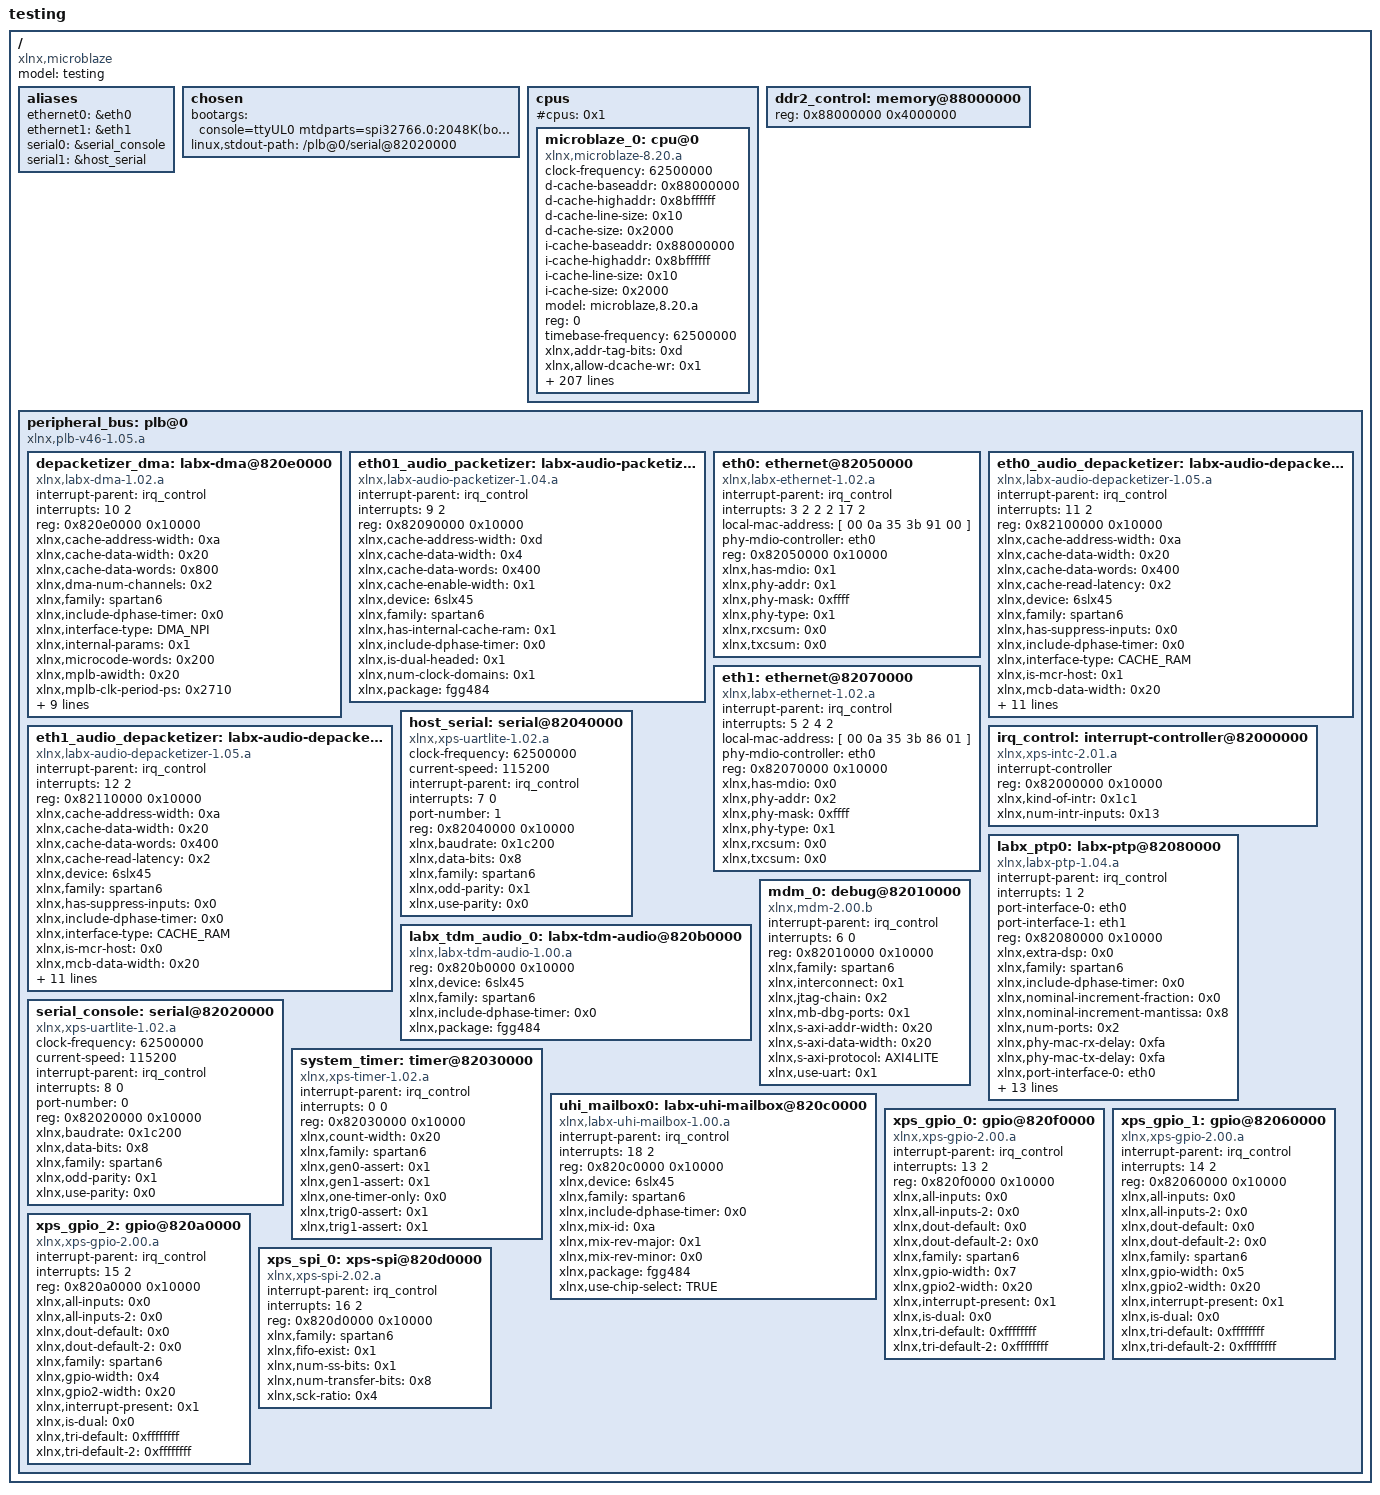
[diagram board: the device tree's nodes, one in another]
/*
 * Device Tree Generator version: 1.3
 *
 * (C) Copyright 2007-2008 Xilinx, Inc.
 * (C) Copyright 2007-2009 Michal Simek
 *
 * Michal SIMEK <monstr@monstr.eu>
 *
 * This program is free software; you can redistribute it and/or
 * modify it under the terms of the GNU General Public License as
 * published by the Free Software Foundation; either version 2 of
 * the License, or (at your option) any later version.
 *
 * This program is distributed in the hope that it will be useful,
 * but WITHOUT ANY WARRANTY; without even the implied warranty of
 * MERCHANTABILITY or FITNESS FOR A PARTICULAR PURPOSE. See the
 * GNU General Public License for more details.
 *
 * You should have received a copy of the GNU General Public License
 * along with this program; if not, write to the Free Software
 * Foundation, Inc., 59 Temple Place, Suite 330, Boston,
 * MA 02111-1307 USA
 *
 * CAUTION: This file is automatically generated by libgen.
 * Version: Xilinx EDK 13.2 EDK_O.61xd
 *
 */

/dts-v1/;
/ {
	#address-cells = <1>;
	#size-cells = <1>;
	compatible = "xlnx,microblaze";
	model = "testing";
	aliases {
		ethernet0 = &eth0;
		ethernet1 = &eth1;
		serial0 = &serial_console;
		serial1 = &host_serial;
	} ;
	chosen {
		bootargs = "console=ttyUL0 mtdparts=spi32766.0:2048K(bootfpga),256K(boot),256K(fdt),3840K(image),2048K(rootfs),2048K(romfs),2048K(fpga),2048K(settingsfs),256K(bootenv) root=mtd4 rootfstype=romfs init=/bin/init";
		linux,stdout-path = "/plb@0/serial@82020000";
	} ;
	cpus {
		#address-cells = <1>;
		#cpus = <0x1>;
		#size-cells = <0>;
		microblaze_0: cpu@0 {
			clock-frequency = <62500000>;
			compatible = "xlnx,microblaze-8.20.a";
			d-cache-baseaddr = <0x88000000>;
			d-cache-highaddr = <0x8bffffff>;
			d-cache-line-size = <0x10>;
			d-cache-size = <0x2000>;
			device_type = "cpu";
			i-cache-baseaddr = <0x88000000>;
			i-cache-highaddr = <0x8bffffff>;
			i-cache-line-size = <0x10>;
			i-cache-size = <0x2000>;
			model = "microblaze,8.20.a";
			reg = <0>;
			timebase-frequency = <62500000>;
			xlnx,addr-tag-bits = <0xd>;
			xlnx,allow-dcache-wr = <0x1>;
			xlnx,allow-icache-wr = <0x1>;
			xlnx,archiver = "0";
			xlnx,area-optimized = <0x0>;
			xlnx,avoid-primitives = <0x0>;
			xlnx,branch-target-cache-size = <0x0>;
			xlnx,cache-byte-size = <0x2000>;
			xlnx,compiler = "0";
			xlnx,compiler-flags = "0";
			xlnx,core-clock-freq-hz = <0x5f5e100>;
			xlnx,d-axi = <0x0>;
			xlnx,d-lmb = <0x1>;
			xlnx,d-plb = <0x1>;
			xlnx,data-size = <0x20>;
			xlnx,dcache-addr-tag = <0xd>;
			xlnx,dcache-always-used = <0x1>;
			xlnx,dcache-byte-size = <0x2000>;
			xlnx,dcache-data-width = <0x0>;
			xlnx,dcache-force-tag-lutram = <0x0>;
			xlnx,dcache-interface = <0x0>;
			xlnx,dcache-line-len = <0x4>;
			xlnx,dcache-use-fsl = <0x1>;
			xlnx,dcache-use-writeback = <0x0>;
			xlnx,dcache-victims = <0x0>;
			xlnx,debug-enabled = <0x1>;
			xlnx,div-zero-exception = <0x1>;
			xlnx,dynamic-bus-sizing = <0x1>;
			xlnx,ecc-use-ce-exception = <0x0>;
			xlnx,edge-is-positive = <0x1>;
			xlnx,endianness = <0x0>;
			xlnx,extra-compiler-flags = "0";
			xlnx,family = "spartan6";
			xlnx,fault-tolerant = <0x0>;
			xlnx,fpu-exception = <0x0>;
			xlnx,freq = <0x3b9aca0>;
			xlnx,fsl-data-size = <0x20>;
			xlnx,fsl-exception = <0x0>;
			xlnx,fsl-links = <0x1>;
			xlnx,i-axi = <0x0>;
			xlnx,i-lmb = <0x1>;
			xlnx,i-plb = <0x1>;
			xlnx,icache-always-used = <0x1>;
			xlnx,icache-data-width = <0x0>;
			xlnx,icache-force-tag-lutram = <0x0>;
			xlnx,icache-interface = <0x0>;
			xlnx,icache-line-len = <0x4>;
			xlnx,icache-streams = <0x0>;
			xlnx,icache-use-fsl = <0x1>;
			xlnx,icache-victims = <0x0>;
			xlnx,ill-opcode-exception = <0x1>;
			xlnx,instance = "microblaze_0";
			xlnx,interconnect = <0x1>;
			xlnx,interconnect-m-axi-dc-read-issuing = <0x2>;
			xlnx,interconnect-m-axi-dc-write-issuing = <0x20>;
			xlnx,interconnect-m-axi-dp-read-issuing = <0x1>;
			xlnx,interconnect-m-axi-dp-write-issuing = <0x1>;
			xlnx,interconnect-m-axi-ic-read-issuing = <0x2>;
			xlnx,interconnect-m-axi-ip-read-issuing = <0x1>;
			xlnx,interrupt-is-edge = <0x0>;
			xlnx,lockstep-slave = <0x0>;
			xlnx,m-axi-d-bus-exception = <0x0>;
			xlnx,m-axi-dc-addr-width = <0x20>;
			xlnx,m-axi-dc-aruser-width = <0x5>;
			xlnx,m-axi-dc-awuser-width = <0x5>;
			xlnx,m-axi-dc-buser-width = <0x1>;
			xlnx,m-axi-dc-data-width = <0x20>;
			xlnx,m-axi-dc-exclusive-access = <0x0>;
			xlnx,m-axi-dc-protocol = "AXI4";
			xlnx,m-axi-dc-ruser-width = <0x1>;
			xlnx,m-axi-dc-supports-narrow-burst = <0x0>;
			xlnx,m-axi-dc-supports-read = <0x1>;
			xlnx,m-axi-dc-supports-threads = <0x0>;
			xlnx,m-axi-dc-supports-user-signals = <0x1>;
			xlnx,m-axi-dc-supports-write = <0x1>;
			xlnx,m-axi-dc-thread-id-width = <0x1>;
			xlnx,m-axi-dc-user-value = <0x1f>;
			xlnx,m-axi-dc-wuser-width = <0x1>;
			xlnx,m-axi-dp-addr-width = <0x20>;
			xlnx,m-axi-dp-data-width = <0x20>;
			xlnx,m-axi-dp-exclusive-access = <0x0>;
			xlnx,m-axi-dp-protocol = "AXI4LITE";
			xlnx,m-axi-dp-supports-narrow-burst = <0x0>;
			xlnx,m-axi-dp-supports-read = <0x1>;
			xlnx,m-axi-dp-supports-threads = <0x0>;
			xlnx,m-axi-dp-supports-write = <0x1>;
			xlnx,m-axi-dp-thread-id-width = <0x1>;
			xlnx,m-axi-i-bus-exception = <0x0>;
			xlnx,m-axi-ic-addr-width = <0x20>;
			xlnx,m-axi-ic-aruser-width = <0x5>;
			xlnx,m-axi-ic-awuser-width = <0x5>;
			xlnx,m-axi-ic-buser-width = <0x1>;
			xlnx,m-axi-ic-data-width = <0x20>;
			xlnx,m-axi-ic-protocol = "AXI4";
			xlnx,m-axi-ic-ruser-width = <0x1>;
			xlnx,m-axi-ic-supports-narrow-burst = <0x0>;
			xlnx,m-axi-ic-supports-read = <0x1>;
			xlnx,m-axi-ic-supports-threads = <0x0>;
			xlnx,m-axi-ic-supports-user-signals = <0x1>;
			xlnx,m-axi-ic-supports-write = <0x0>;
			xlnx,m-axi-ic-thread-id-width = <0x1>;
			xlnx,m-axi-ic-user-value = <0x1f>;
			xlnx,m-axi-ic-wuser-width = <0x1>;
			xlnx,m-axi-ip-addr-width = <0x20>;
			xlnx,m-axi-ip-data-width = <0x20>;
			xlnx,m-axi-ip-protocol = "AXI4LITE";
			xlnx,m-axi-ip-supports-narrow-burst = <0x0>;
			xlnx,m-axi-ip-supports-read = <0x1>;
			xlnx,m-axi-ip-supports-threads = <0x0>;
			xlnx,m-axi-ip-supports-write = <0x0>;
			xlnx,m-axi-ip-thread-id-width = <0x1>;
			xlnx,m0-axis-data-width = <0x20>;
			xlnx,m0-axis-protocol = "GENERIC";
			xlnx,m1-axis-data-width = <0x20>;
			xlnx,m1-axis-protocol = "GENERIC";
			xlnx,m10-axis-data-width = <0x20>;
			xlnx,m10-axis-protocol = "GENERIC";
			xlnx,m11-axis-data-width = <0x20>;
			xlnx,m11-axis-protocol = "GENERIC";
			xlnx,m12-axis-data-width = <0x20>;
			xlnx,m12-axis-protocol = "GENERIC";
			xlnx,m13-axis-data-width = <0x20>;
			xlnx,m13-axis-protocol = "GENERIC";
			xlnx,m14-axis-data-width = <0x20>;
			xlnx,m14-axis-protocol = "GENERIC";
			xlnx,m15-axis-data-width = <0x20>;
			xlnx,m15-axis-protocol = "GENERIC";
			xlnx,m2-axis-data-width = <0x20>;
			xlnx,m2-axis-protocol = "GENERIC";
			xlnx,m3-axis-data-width = <0x20>;
			xlnx,m3-axis-protocol = "GENERIC";
			xlnx,m4-axis-data-width = <0x20>;
			xlnx,m4-axis-protocol = "GENERIC";
			xlnx,m5-axis-data-width = <0x20>;
			xlnx,m5-axis-protocol = "GENERIC";
			xlnx,m6-axis-data-width = <0x20>;
			xlnx,m6-axis-protocol = "GENERIC";
			xlnx,m7-axis-data-width = <0x20>;
			xlnx,m7-axis-protocol = "GENERIC";
			xlnx,m8-axis-data-width = <0x20>;
			xlnx,m8-axis-protocol = "GENERIC";
			xlnx,m9-axis-data-width = <0x20>;
			xlnx,m9-axis-protocol = "GENERIC";
			xlnx,mmu-dtlb-size = <0x4>;
			xlnx,mmu-itlb-size = <0x2>;
			xlnx,mmu-privileged-instr = <0x0>;
			xlnx,mmu-tlb-access = <0x3>;
			xlnx,mmu-zones = <0x10>;
			xlnx,multiplier = "false";
			xlnx,number-of-pc-brk = <0x1>;
			xlnx,number-of-rd-addr-brk = <0x0>;
			xlnx,number-of-wr-addr-brk = <0x0>;
			xlnx,opcode-0x0-illegal = <0x1>;
			xlnx,optimization = <0x0>;
			xlnx,pvr = <0x0>;
			xlnx,pvr-user1 = <0x0>;
			xlnx,pvr-user2 = <0x0>;
			xlnx,reset-msr = <0x0>;
			xlnx,s0-axis-data-width = <0x20>;
			xlnx,s0-axis-protocol = "GENERIC";
			xlnx,s1-axis-data-width = <0x20>;
			xlnx,s1-axis-protocol = "GENERIC";
			xlnx,s10-axis-data-width = <0x20>;
			xlnx,s10-axis-protocol = "GENERIC";
			xlnx,s11-axis-data-width = <0x20>;
			xlnx,s11-axis-protocol = "GENERIC";
			xlnx,s12-axis-data-width = <0x20>;
			xlnx,s12-axis-protocol = "GENERIC";
			xlnx,s13-axis-data-width = <0x20>;
			xlnx,s13-axis-protocol = "GENERIC";
			xlnx,s14-axis-data-width = <0x20>;
			xlnx,s14-axis-protocol = "GENERIC";
			xlnx,s15-axis-data-width = <0x20>;
			xlnx,s15-axis-protocol = "GENERIC";
			xlnx,s2-axis-data-width = <0x20>;
			xlnx,s2-axis-protocol = "GENERIC";
			xlnx,s3-axis-data-width = <0x20>;
			xlnx,s3-axis-protocol = "GENERIC";
			xlnx,s4-axis-data-width = <0x20>;
			xlnx,s4-axis-protocol = "GENERIC";
			xlnx,s5-axis-data-width = <0x20>;
			xlnx,s5-axis-protocol = "GENERIC";
			xlnx,s6-axis-data-width = <0x20>;
			xlnx,s6-axis-protocol = "GENERIC";
			xlnx,s7-axis-data-width = <0x20>;
			xlnx,s7-axis-protocol = "GENERIC";
			xlnx,s8-axis-data-width = <0x20>;
			xlnx,s8-axis-protocol = "GENERIC";
			xlnx,s9-axis-data-width = <0x20>;
			xlnx,s9-axis-protocol = "GENERIC";
			xlnx,sco = <0x0>;
			xlnx,stream-interconnect = <0x0>;
			xlnx,unaligned-exceptions = <0x1>;
			xlnx,use-barrel = <0x1>;
			xlnx,use-branch-target-cache = <0x0>;
			xlnx,use-dcache = <0x1>;
			xlnx,use-div = <0x1>;
			xlnx,use-ext-brk = <0x1>;
			xlnx,use-ext-nm-brk = <0x1>;
			xlnx,use-extended-fsl-instr = <0x0>;
			xlnx,use-fpu = <0x0>;
			xlnx,use-hw-mul = <0x1>;
			xlnx,use-icache = <0x1>;
			xlnx,use-interrupt = <0x1>;
			xlnx,use-mmu = <0x0>;
			xlnx,use-msr-instr = <0x1>;
			xlnx,use-pcmp-instr = <0x1>;
			xlnx,use-stack-protection = <0x0>;
			xlnx,xmdstub-peripheral = "false";
		} ;
	} ;
	ddr2_control: memory@88000000 {
		device_type = "memory";
		reg = < 0x88000000 0x4000000 >;
	} ;
	peripheral_bus: plb@0 {
		#address-cells = <1>;
		#size-cells = <1>;
		compatible = "xlnx,plb-v46-1.05.a", "xlnx,plb-v46-1.00.a", "simple-bus";
		ranges ;
		depacketizer_dma: labx-dma@820e0000 {
			compatible = "xlnx,labx-dma-1.02.a";
			interrupt-parent = <&irq_control>;
			interrupts = < 10 2 >;
			reg = < 0x820e0000 0x10000 >;
			xlnx,cache-address-width = <0xa>;
			xlnx,cache-data-width = <0x20>;
			xlnx,cache-data-words = <0x800>;
			xlnx,dma-num-channels = <0x2>;
			xlnx,family = "spartan6";
			xlnx,include-dphase-timer = <0x0>;
			xlnx,interface-type = "DMA_NPI";
			xlnx,internal-params = <0x1>;
			xlnx,microcode-words = <0x200>;
			xlnx,mplb-awidth = <0x20>;
			xlnx,mplb-clk-period-ps = <0x2710>;
			xlnx,mplb-dwidth = <0x80>;
			xlnx,mplb-native-dwidth = <0x20>;
			xlnx,mplb-p2p = <0x0>;
			xlnx,mplb-smallest-slave = <0x20>;
			xlnx,num-cache-interfaces = <0x2>;
			xlnx,num-param-interfaces = <0x2>;
			xlnx,param-address-width = <0x9>;
			xlnx,param-words = <0x200>;
			xlnx,parameter-interlock-fifo = <0x1>;
		} ;
		eth01_audio_packetizer: labx-audio-packetizer@82090000 {
			compatible = "xlnx,labx-audio-packetizer-1.04.a";
			interrupt-parent = <&irq_control>;
			interrupts = < 9 2 >;
			reg = < 0x82090000 0x10000 >;
			xlnx,cache-address-width = <0xd>;
			xlnx,cache-data-width = <0x4>;
			xlnx,cache-data-words = <0x400>;
			xlnx,cache-enable-width = <0x1>;
			xlnx,device = "6slx45";
			xlnx,family = "spartan6";
			xlnx,has-internal-cache-ram = <0x1>;
			xlnx,include-dphase-timer = <0x0>;
			xlnx,is-dual-headed = <0x1>;
			xlnx,num-clock-domains = <0x1>;
			xlnx,package = "fgg484";
		} ;
		eth0: ethernet@82050000 {
			compatible = "xlnx,labx-ethernet-1.02.a";
			device_type = "network";
			interrupt-parent = <&irq_control>;
			interrupts = < 3 2 2 2 17 2 >;
			local-mac-address = [ 00 0a 35 3b 91 00 ];
			phy-mdio-controller = <&eth0>;
			reg = < 0x82050000 0x10000 >;
			xlnx,has-mdio = <0x1>;
			xlnx,phy-addr = <0x1>;
			xlnx,phy-mask = <0xffff>;
			xlnx,phy-type = <0x1>;
			xlnx,rxcsum = <0x0>;
			xlnx,txcsum = <0x0>;
		} ;
		eth0_audio_depacketizer: labx-audio-depacketizer@82100000 {
			compatible = "xlnx,labx-audio-depacketizer-1.05.a";
			interrupt-parent = <&irq_control>;
			interrupts = < 11 2 >;
			reg = < 0x82100000 0x10000 >;
			xlnx,cache-address-width = <0xa>;
			xlnx,cache-data-width = <0x20>;
			xlnx,cache-data-words = <0x400>;
			xlnx,cache-read-latency = <0x2>;
			xlnx,device = "6slx45";
			xlnx,family = "spartan6";
			xlnx,has-suppress-inputs = <0x0>;
			xlnx,include-dphase-timer = <0x0>;
			xlnx,interface-type = "CACHE_RAM";
			xlnx,is-mcr-host = <0x1>;
			xlnx,mcb-data-width = <0x20>;
			xlnx,mplb-awidth = <0x20>;
			xlnx,mplb-clk-period-ps = <0x2710>;
			xlnx,mplb-dwidth = <0x80>;
			xlnx,mplb-native-dwidth = <0x20>;
			xlnx,mplb-p2p = <0x0>;
			xlnx,mplb-smallest-slave = <0x20>;
			xlnx,npi-data-width = <0x20>;
			xlnx,num-clock-domains = <0x1>;
			xlnx,num-streams = <0x40>;
			xlnx,package = "fgg484";
			xlnx,param-address-width = <0x9>;
		} ;
		eth1: ethernet@82070000 {
			compatible = "xlnx,labx-ethernet-1.02.a";
			device_type = "network";
			interrupt-parent = <&irq_control>;
			interrupts = < 5 2 4 2 >;
			local-mac-address = [ 00 0a 35 3b 86 01 ];
			phy-mdio-controller = <&eth0>;
			reg = < 0x82070000 0x10000 >;
			xlnx,has-mdio = <0x0>;
			xlnx,phy-addr = <0x2>;
			xlnx,phy-mask = <0xffff>;
			xlnx,phy-type = <0x1>;
			xlnx,rxcsum = <0x0>;
			xlnx,txcsum = <0x0>;
		} ;
		eth1_audio_depacketizer: labx-audio-depacketizer@82110000 {
			compatible = "xlnx,labx-audio-depacketizer-1.05.a";
			interrupt-parent = <&irq_control>;
			interrupts = < 12 2 >;
			reg = < 0x82110000 0x10000 >;
			xlnx,cache-address-width = <0xa>;
			xlnx,cache-data-width = <0x20>;
			xlnx,cache-data-words = <0x400>;
			xlnx,cache-read-latency = <0x2>;
			xlnx,device = "6slx45";
			xlnx,family = "spartan6";
			xlnx,has-suppress-inputs = <0x0>;
			xlnx,include-dphase-timer = <0x0>;
			xlnx,interface-type = "CACHE_RAM";
			xlnx,is-mcr-host = <0x0>;
			xlnx,mcb-data-width = <0x20>;
			xlnx,mplb-awidth = <0x20>;
			xlnx,mplb-clk-period-ps = <0x2710>;
			xlnx,mplb-dwidth = <0x80>;
			xlnx,mplb-native-dwidth = <0x20>;
			xlnx,mplb-p2p = <0x0>;
			xlnx,mplb-smallest-slave = <0x20>;
			xlnx,npi-data-width = <0x20>;
			xlnx,num-clock-domains = <0x1>;
			xlnx,num-streams = <0x40>;
			xlnx,package = "fgg484";
			xlnx,param-address-width = <0x9>;
		} ;
		host_serial: serial@82040000 {
			clock-frequency = <62500000>;
			compatible = "xlnx,xps-uartlite-1.02.a", "xlnx,xps-uartlite-1.00.a";
			current-speed = <115200>;
			device_type = "serial";
			interrupt-parent = <&irq_control>;
			interrupts = < 7 0 >;
			port-number = <1>;
			reg = < 0x82040000 0x10000 >;
			xlnx,baudrate = <0x1c200>;
			xlnx,data-bits = <0x8>;
			xlnx,family = "spartan6";
			xlnx,odd-parity = <0x1>;
			xlnx,use-parity = <0x0>;
		} ;
		irq_control: interrupt-controller@82000000 {
			#interrupt-cells = <0x2>;
			compatible = "xlnx,xps-intc-2.01.a", "xlnx,xps-intc-1.00.a";
			interrupt-controller ;
			reg = < 0x82000000 0x10000 >;
			xlnx,kind-of-intr = <0x1c1>;
			xlnx,num-intr-inputs = <0x13>;
		} ;
		labx_ptp0: labx-ptp@82080000 {
			compatible = "xlnx,labx-ptp-1.04.a";
			interrupt-parent = <&irq_control>;
			interrupts = < 1 2 >;
			port-interface-0 = <&eth0>;
			port-interface-1 = <&eth1>;
			reg = < 0x82080000 0x10000 >;
			xlnx,extra-dsp = <0x0>;
			xlnx,family = "spartan6";
			xlnx,include-dphase-timer = <0x0>;
			xlnx,nominal-increment-fraction = <0x0>;
			xlnx,nominal-increment-mantissa = <0x8>;
			xlnx,num-ports = <0x2>;
			xlnx,phy-mac-rx-delay = <0xfa>;
			xlnx,phy-mac-tx-delay = <0xfa>;
			xlnx,port-interface-0 = "eth0";
			xlnx,port-interface-1 = "eth1";
			xlnx,port-interface-2 = "Invalid";
			xlnx,port-interface-3 = "Invalid";
			xlnx,port-interface-4 = "Invalid";
			xlnx,port-interface-5 = "Invalid";
			xlnx,port-interface-6 = "Invalid";
			xlnx,port-interface-7 = "Invalid";
			xlnx,port-width = <0x8>;
			xlnx,rtc-d-coefficient = <0xf0000000>;
			xlnx,rtc-i-coefficient = <0xf0000000>;
			xlnx,rtc-p-coefficient = <0xfff00000>;
			xlnx,timer-divider = <0x271>;
			xlnx,timer-prescaler = <0x3e8>;
		} ;
		labx_tdm_audio_0: labx-tdm-audio@820b0000 {
			compatible = "xlnx,labx-tdm-audio-1.00.a";
			reg = < 0x820b0000 0x10000 >;
			xlnx,device = "6slx45";
			xlnx,family = "spartan6";
			xlnx,include-dphase-timer = <0x0>;
			xlnx,package = "fgg484";
		} ;
		mdm_0: debug@82010000 {
			compatible = "xlnx,mdm-2.00.b";
			interrupt-parent = <&irq_control>;
			interrupts = < 6 0 >;
			reg = < 0x82010000 0x10000 >;
			xlnx,family = "spartan6";
			xlnx,interconnect = <0x1>;
			xlnx,jtag-chain = <0x2>;
			xlnx,mb-dbg-ports = <0x1>;
			xlnx,s-axi-addr-width = <0x20>;
			xlnx,s-axi-data-width = <0x20>;
			xlnx,s-axi-protocol = "AXI4LITE";
			xlnx,use-uart = <0x1>;
		} ;
		serial_console: serial@82020000 {
			clock-frequency = <62500000>;
			compatible = "xlnx,xps-uartlite-1.02.a", "xlnx,xps-uartlite-1.00.a";
			current-speed = <115200>;
			device_type = "serial";
			interrupt-parent = <&irq_control>;
			interrupts = < 8 0 >;
			port-number = <0>;
			reg = < 0x82020000 0x10000 >;
			xlnx,baudrate = <0x1c200>;
			xlnx,data-bits = <0x8>;
			xlnx,family = "spartan6";
			xlnx,odd-parity = <0x1>;
			xlnx,use-parity = <0x0>;
		} ;
		system_timer: timer@82030000 {
			compatible = "xlnx,xps-timer-1.02.a", "xlnx,xps-timer-1.00.a";
			interrupt-parent = <&irq_control>;
			interrupts = < 0 0 >;
			reg = < 0x82030000 0x10000 >;
			xlnx,count-width = <0x20>;
			xlnx,family = "spartan6";
			xlnx,gen0-assert = <0x1>;
			xlnx,gen1-assert = <0x1>;
			xlnx,one-timer-only = <0x0>;
			xlnx,trig0-assert = <0x1>;
			xlnx,trig1-assert = <0x1>;
		} ;
		uhi_mailbox0: labx-uhi-mailbox@820c0000 {
			compatible = "xlnx,labx-uhi-mailbox-1.00.a";
			interrupt-parent = <&irq_control>;
			interrupts = < 18 2 >;
			reg = < 0x820c0000 0x10000 >;
			xlnx,device = "6slx45";
			xlnx,family = "spartan6";
			xlnx,include-dphase-timer = <0x0>;
			xlnx,mix-id = <0xa>;
			xlnx,mix-rev-major = <0x1>;
			xlnx,mix-rev-minor = <0x0>;
			xlnx,package = "fgg484";
			xlnx,use-chip-select = "TRUE";
		} ;
		xps_gpio_0: gpio@820f0000 {
			compatible = "xlnx,xps-gpio-2.00.a", "xlnx,xps-gpio-1.00.a";
			interrupt-parent = <&irq_control>;
			interrupts = < 13 2 >;
			reg = < 0x820f0000 0x10000 >;
			xlnx,all-inputs = <0x0>;
			xlnx,all-inputs-2 = <0x0>;
			xlnx,dout-default = <0x0>;
			xlnx,dout-default-2 = <0x0>;
			xlnx,family = "spartan6";
			xlnx,gpio-width = <0x7>;
			xlnx,gpio2-width = <0x20>;
			xlnx,interrupt-present = <0x1>;
			xlnx,is-dual = <0x0>;
			xlnx,tri-default = <0xffffffff>;
			xlnx,tri-default-2 = <0xffffffff>;
		} ;
		xps_gpio_1: gpio@82060000 {
			compatible = "xlnx,xps-gpio-2.00.a", "xlnx,xps-gpio-1.00.a";
			interrupt-parent = <&irq_control>;
			interrupts = < 14 2 >;
			reg = < 0x82060000 0x10000 >;
			xlnx,all-inputs = <0x0>;
			xlnx,all-inputs-2 = <0x0>;
			xlnx,dout-default = <0x0>;
			xlnx,dout-default-2 = <0x0>;
			xlnx,family = "spartan6";
			xlnx,gpio-width = <0x5>;
			xlnx,gpio2-width = <0x20>;
			xlnx,interrupt-present = <0x1>;
			xlnx,is-dual = <0x0>;
			xlnx,tri-default = <0xffffffff>;
			xlnx,tri-default-2 = <0xffffffff>;
		} ;
		xps_gpio_2: gpio@820a0000 {
			compatible = "xlnx,xps-gpio-2.00.a", "xlnx,xps-gpio-1.00.a";
			interrupt-parent = <&irq_control>;
			interrupts = < 15 2 >;
			reg = < 0x820a0000 0x10000 >;
			xlnx,all-inputs = <0x0>;
			xlnx,all-inputs-2 = <0x0>;
			xlnx,dout-default = <0x0>;
			xlnx,dout-default-2 = <0x0>;
			xlnx,family = "spartan6";
			xlnx,gpio-width = <0x4>;
			xlnx,gpio2-width = <0x20>;
			xlnx,interrupt-present = <0x1>;
			xlnx,is-dual = <0x0>;
			xlnx,tri-default = <0xffffffff>;
			xlnx,tri-default-2 = <0xffffffff>;
		} ;
		xps_spi_0: xps-spi@820d0000 {
			compatible = "xlnx,xps-spi-2.02.a", "xlnx,xps-spi-2.00.a";
			interrupt-parent = <&irq_control>;
			interrupts = < 16 2 >;
			reg = < 0x820d0000 0x10000 >;
			xlnx,family = "spartan6";
			xlnx,fifo-exist = <0x1>;
			xlnx,num-ss-bits = <0x1>;
			xlnx,num-transfer-bits = <0x8>;
			xlnx,sck-ratio = <0x4>;
		} ;
	} ;
}  ;
